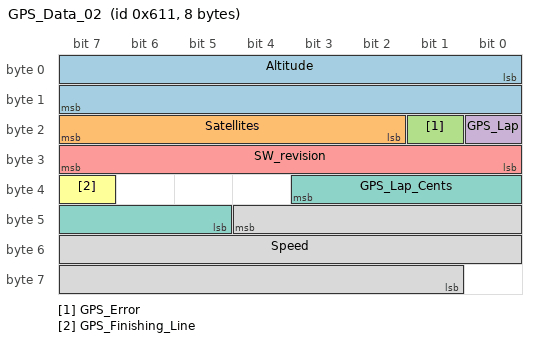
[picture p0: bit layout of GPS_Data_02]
BO_ 1553 GPS_Data_02: 8 GPS_DL
 SG_ Altitude : 0|16@1+ (0.1,0) [0|6553.5] "ä" Vector__XXX
 SG_ Satellites : 18|6@1+ (0.5,0) [0|31] "" Vector__XXX
 SG_ GPS_Error : 17|1@1+ (1,0) [0|1] "" Vector__XXX
 SG_ GPS_Lap : 16|1@1+ (1,0) [0|1] "" Vector__XXX
 SG_ SW_revision : 24|8@1+ (1,0) [0|255] "" Vector__XXX
 SG_ GPS_Finishing_Line : 39|1@1+ (1,0) [0|1] "" Vector__XXX
 SG_ GPS_Lap_Cents : 35|7@0+ (1,0) [0|127] "" Vector__XXX
 SG_ Speed : 44|20@0+ (1,0) [0|511] "" Vector__XXX
